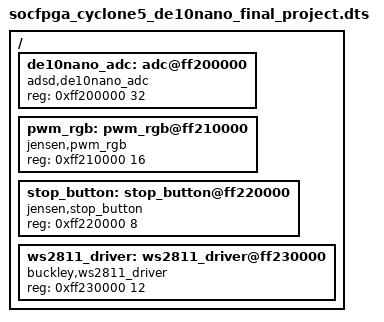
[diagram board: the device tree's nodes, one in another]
#include "socfpga_cyclone5_de10nano.dtsi"

/{
de10nano_adc: adc@ff200000 {
    compatible = "adsd,de10nano_adc";
    reg = <0xff200000 32>;

};

pwm_rgb: pwm_rgb@ff210000 {
compatible = "jensen,pwm_rgb";
reg = <0xff210000 16>;
};

stop_button: stop_button@ff220000 {
compatible = "jensen,stop_button";
reg = <0xff220000 8>;
};

ws2811_driver: ws2811_driver@ff230000 {
compatible = "buckley,ws2811_driver";
reg = <0xff230000 12>;
};
};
